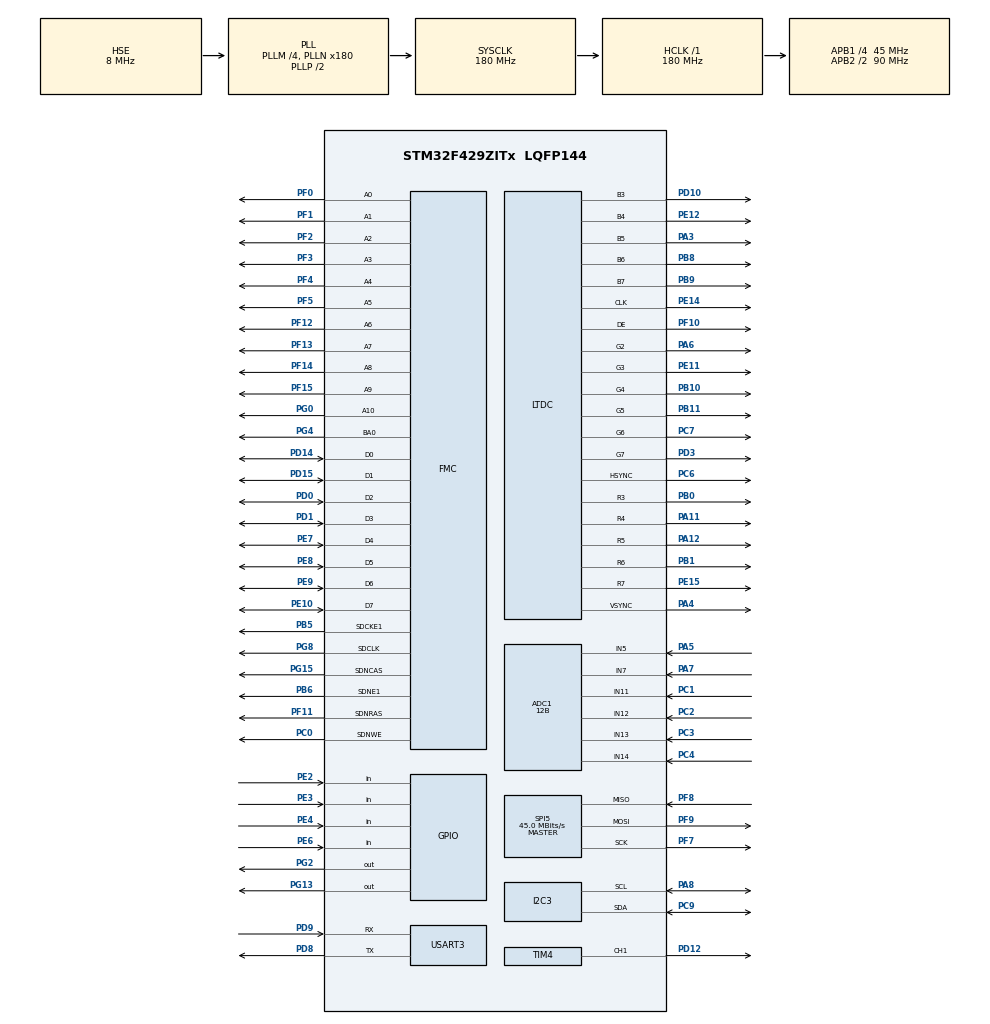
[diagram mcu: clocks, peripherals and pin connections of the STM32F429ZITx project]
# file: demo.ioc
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ADC1.Channel-4\#ChannelRegularConversion=ADC_CHANNEL_5
ADC1.Channel-5\#ChannelRegularConversion=ADC_CHANNEL_7
ADC1.Channel-6\#ChannelRegularConversion=ADC_CHANNEL_11
ADC1.Channel-7\#ChannelRegularConversion=ADC_CHANNEL_12
ADC1.Channel-8\#ChannelRegularConversion=ADC_CHANNEL_13
ADC1.Channel-9\#ChannelRegularConversion=ADC_CHANNEL_14
ADC1.ContinuousConvMode=DISABLE
ADC1.DMAContinuousRequests=DISABLE
ADC1.EOCSelection=ADC_EOC_SEQ_CONV
ADC1.NbrOfConversion=6
ADC1.NbrOfConversionFlag=1
ADC1.Rank-5\#ChannelRegularConversion=2
ADC1.Rank-6\#ChannelRegularConversion=3
ADC1.Rank-7\#ChannelRegularConversion=4
ADC1.Rank-8\#ChannelRegularConversion=5
ADC1.Rank-9\#ChannelRegularConversion=6
ADC1.Resolution=ADC_RESOLUTION_12B
ADC1.SamplingTime-4\#ChannelRegularConversion=ADC_SAMPLETIME_3CYCLES
ADC1.SamplingTime-5\#ChannelRegularConversion=ADC_SAMPLETIME_3CYCLES
ADC1.SamplingTime-6\#ChannelRegularConversion=ADC_SAMPLETIME_3CYCLES
ADC1.SamplingTime-7\#ChannelRegularConversion=ADC_SAMPLETIME_3CYCLES
ADC1.SamplingTime-8\#ChannelRegularConversion=ADC_SAMPLETIME_3CYCLES
ADC1.SamplingTime-9\#ChannelRegularConversion=ADC_SAMPLETIME_3CYCLES
ADC1.master=1
DMA2D.ColorMode=DMA2D_OUTPUT_RGB565
Dma.ADC1.0.Direction=DMA_PERIPH_TO_MEMORY
Dma.ADC1.0.FIFOMode=DMA_FIFOMODE_DISABLE
Dma.ADC1.0.Instance=DMA2_Stream4
Dma.ADC1.0.MemDataAlignment=DMA_MDATAALIGN_HALFWORD
Dma.ADC1.0.MemInc=DMA_MINC_ENABLE
Dma.ADC1.0.Mode=DMA_CIRCULAR
Dma.ADC1.0.PeriphDataAlignment=DMA_PDATAALIGN_HALFWORD
Dma.ADC1.0.PeriphInc=DMA_PINC_DISABLE
Dma.ADC1.0.Priority=DMA_PRIORITY_HIGH
Dma.Request0=ADC1
Dma.Request1=TIM4_CH1
Dma.Request2=USART3_TX
Dma.TIM4_CH1.1.Direction=DMA_MEMORY_TO_PERIPH
Dma.TIM4_CH1.1.FIFOMode=DMA_FIFOMODE_DISABLE
Dma.TIM4_CH1.1.Instance=DMA1_Stream0
Dma.TIM4_CH1.1.MemDataAlignment=DMA_MDATAALIGN_HALFWORD
Dma.TIM4_CH1.1.MemInc=DMA_MINC_ENABLE
Dma.TIM4_CH1.1.Mode=DMA_NORMAL
Dma.TIM4_CH1.1.PeriphDataAlignment=DMA_PDATAALIGN_HALFWORD
Dma.TIM4_CH1.1.PeriphInc=DMA_PINC_DISABLE
Dma.TIM4_CH1.1.Priority=DMA_PRIORITY_LOW
Dma.USART3_TX.2.Direction=DMA_MEMORY_TO_PERIPH
Dma.USART3_TX.2.FIFOMode=DMA_FIFOMODE_DISABLE
Dma.USART3_TX.2.Instance=DMA1_Stream3
Dma.USART3_TX.2.MemDataAlignment=DMA_MDATAALIGN_BYTE
Dma.USART3_TX.2.MemInc=DMA_MINC_ENABLE
Dma.USART3_TX.2.Mode=DMA_NORMAL
Dma.USART3_TX.2.PeriphDataAlignment=DMA_PDATAALIGN_BYTE
Dma.USART3_TX.2.PeriphInc=DMA_PINC_DISABLE
Dma.USART3_TX.2.Priority=DMA_PRIORITY_MEDIUM
Mcu.Family=STM32F4
Mcu.Name=STM32F429ZITx
Mcu.Package=LQFP144
NVIC.DMA1_Stream0_IRQn=true\:0\:0\:false\:false\:true\:false\:true\:true
NVIC.DMA1_Stream3_IRQn=true\:0\:0\:false\:false\:true\:false\:true\:true
NVIC.DMA2_Stream4_IRQn=true\:0\:0\:false\:false\:true\:false\:true\:true
NVIC.PriorityGroup=NVIC_PRIORITYGROUP_4
NVIC.USART3_IRQn=true\:0\:0\:false\:false\:true\:true\:true\:true
PA11.Mode=RGB565
PA11.Signal=LTDC_R4
PA12.Mode=RGB565
PA12.Signal=LTDC_R5
PA13.Mode=Serial_Wire
PA13.Signal=SYS_JTMS-SWDIO
PA14.Mode=Serial_Wire
PA14.Signal=SYS_JTCK-SWCLK
PA3.Mode=RGB565
PA3.Signal=LTDC_B5
PA4.Mode=RGB565
PA4.Signal=LTDC_VSYNC
PA5.Signal=ADCx_IN5
PA6.Mode=RGB565
PA6.Signal=LTDC_G2
PA7.Signal=ADCx_IN7
PA8.Mode=I2C
PA8.Signal=I2C3_SCL
PB0.Mode=RGB565
PB0.Signal=LTDC_R3
PB1.Mode=RGB565
PB1.Signal=LTDC_R6
PB10.Mode=RGB565
PB10.Signal=LTDC_G4
PB11.Mode=RGB565
PB11.Signal=LTDC_G5
PB5.Mode=SdramChipSelect2_1
PB5.Signal=FMC_SDCKE1
PB6.Mode=SdramChipSelect2_1
PB6.Signal=FMC_SDNE1
PB8.Mode=RGB565
PB8.Signal=LTDC_B6
PB9.Mode=RGB565
PB9.Signal=LTDC_B7
PC0.Signal=FMC_SDNWE
PC1.Signal=ADCx_IN11
PC2.Signal=ADCx_IN12
PC3.Signal=ADCx_IN13
PC4.Signal=ADCx_IN14
PC6.Mode=RGB565
PC6.Signal=LTDC_HSYNC
PC7.Mode=RGB565
PC7.Signal=LTDC_G6
PC9.Mode=I2C
PC9.Signal=I2C3_SDA
PD0.Signal=FMC_D2_DA2
PD1.Signal=FMC_D3_DA3
PD10.Mode=RGB565
PD10.Signal=LTDC_B3
PD12.Signal=S_TIM4_CH1
PD14.Signal=FMC_D0_DA0
PD15.Signal=FMC_D1_DA1
PD3.Mode=RGB565
PD3.Signal=LTDC_G7
PD8.Mode=Asynchronous
PD8.Signal=USART3_TX
PD9.Mode=Asynchronous
PD9.Signal=USART3_RX
PE10.Signal=FMC_D7_DA7
PE11.Mode=RGB565
PE11.Signal=LTDC_G3
PE12.Mode=RGB565
PE12.Signal=LTDC_B4
PE14.Mode=RGB565
PE14.Signal=LTDC_CLK
PE15.Mode=RGB565
PE15.Signal=LTDC_R7
PE2.Signal=GPIO_Input
PE3.Signal=GPIO_Input
PE4.Signal=GPIO_Input
PE6.Signal=GPIO_Input
PE7.Signal=FMC_D4_DA4
PE8.Signal=FMC_D5_DA5
PE9.Signal=FMC_D6_DA6
PF0.Signal=FMC_A0
PF1.Signal=FMC_A1
PF10.Mode=RGB565
PF10.Signal=LTDC_DE
PF11.Signal=FMC_SDNRAS
PF12.Signal=FMC_A6
PF13.Signal=FMC_A7
PF14.Signal=FMC_A8
PF15.Signal=FMC_A9
PF2.Signal=FMC_A2
PF3.Signal=FMC_A3
PF4.Signal=FMC_A4
PF5.Signal=FMC_A5
PF7.Mode=Full_Duplex_Master
PF7.Signal=SPI5_SCK
PF8.Mode=Full_Duplex_Master
PF8.Signal=SPI5_MISO
PF9.Mode=Full_Duplex_Master
PF9.Signal=SPI5_MOSI
PG0.Signal=FMC_A10
PG13.GPIO_Speed=GPIO_SPEED_FREQ_HIGH
PG13.Signal=GPIO_Output
PG15.Signal=FMC_SDNCAS
PG2.Signal=GPIO_Output
PG4.Signal=FMC_A14_BA0
PG8.Signal=FMC_SDCLK
PH0/OSC_IN.Mode=HSE-External-Clock-Source
PH0/OSC_IN.Signal=RCC_OSC_IN
PH1/OSC_OUT.Mode=HSE-External-Clock-Source
PH1/OSC_OUT.Signal=RCC_OSC_OUT
ProjectManager.HeapSize=0x200
ProjectManager.StackSize=0x400
ProjectManager.TargetToolchain=STM32CubeIDE
RCC.48MHZClocksFreq_Value=90000000
RCC.AHBFreq_Value=180000000
RCC.APB1CLKDivider=RCC_HCLK_DIV4
RCC.APB1Freq_Value=45000000
RCC.APB1TimFreq_Value=90000000
RCC.APB2CLKDivider=RCC_HCLK_DIV2
RCC.APB2Freq_Value=90000000
RCC.APB2TimFreq_Value=180000000
RCC.CortexFreq_Value=180000000
RCC.HCLKFreq_Value=180000000
RCC.HSE_VALUE=8000000
RCC.HSI_VALUE=16000000
RCC.LSE_VALUE=32768
RCC.PLLM=4
RCC.PLLN=180
RCC.PLLSAIN=50
RCC.PLLSAIR=4
RCC.PLLSourceVirtual=RCC_PLLSOURCE_HSE
RCC.SYSCLKFreq_VALUE=180000000
RCC.SYSCLKSource=RCC_SYSCLKSOURCE_PLLCLK
RCC.VCOOutputFreq_Value=360000000
SH.ADCx_IN11.0=ADC1_IN11,IN11
SH.ADCx_IN12.0=ADC1_IN12,IN12
SH.ADCx_IN13.0=ADC1_IN13,IN13
SH.ADCx_IN14.0=ADC1_IN14,IN14
SH.ADCx_IN5.0=ADC1_IN5,IN5
SH.ADCx_IN7.0=ADC1_IN7,IN7
SH.FMC_A0.0=FMC_A0,11b-sda1
SH.FMC_A1.0=FMC_A1,11b-sda1
SH.FMC_A10.0=FMC_A10,11b-sda1
SH.FMC_A14_BA0.0=FMC_BA0,TwoSdramBanks1
SH.FMC_A2.0=FMC_A2,11b-sda1
SH.FMC_A3.0=FMC_A3,11b-sda1
SH.FMC_A4.0=FMC_A4,11b-sda1
SH.FMC_A5.0=FMC_A5,11b-sda1
SH.FMC_A6.0=FMC_A6,11b-sda1
SH.FMC_A7.0=FMC_A7,11b-sda1
SH.FMC_A8.0=FMC_A8,11b-sda1
SH.FMC_A9.0=FMC_A9,11b-sda1
SH.FMC_D0_DA0.0=FMC_D0,sd-8b-d1
SH.FMC_D1_DA1.0=FMC_D1,sd-8b-d1
SH.FMC_D2_DA2.0=FMC_D2,sd-8b-d1
SH.FMC_D3_DA3.0=FMC_D3,sd-8b-d1
SH.FMC_D4_DA4.0=FMC_D4,sd-8b-d1
SH.FMC_D5_DA5.0=FMC_D5,sd-8b-d1
SH.FMC_D6_DA6.0=FMC_D6,sd-8b-d1
SH.FMC_D7_DA7.0=FMC_D7,sd-8b-d1
SH.FMC_SDCLK.0=FMC_SDCLK,11b-sda1
SH.FMC_SDNCAS.0=FMC_SDNCAS,11b-sda1
SH.FMC_SDNRAS.0=FMC_SDNRAS,11b-sda1
SH.FMC_SDNWE.0=FMC_SDNWE,11b-sda1
SH.S_TIM4_CH1.0=TIM4_CH1,PWM Generation1 CH1
SPI5.CalculateBaudRate=45.0 MBits/s
SPI5.Direction=SPI_DIRECTION_2LINES
SPI5.Mode=SPI_MODE_MASTER
SPI5.VirtualType=VM_MASTER
TIM4.Channel-PWM\ Generation1\ CH1=TIM_CHANNEL_1
TIM4.Period=112-1
USART3.VirtualMode=VM_ASYNC
VP_DMA2D_VS_DMA2D.Mode=DMA2D_Activate
VP_TIM4_VS_ClockSourceINT.Mode=Internal
board=custom

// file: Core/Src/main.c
/* USER CODE BEGIN Header */
/**
 ******************************************************************************
 * @file           : main.c
 * @brief          : Main program body
 ******************************************************************************
 * @attention
 *
 * Copyright (c) 2023 STMicroelectronics.
 * All rights reserved.
 *
 * This software is licensed under terms that can be found in the LICENSE file
 * in the root directory of this software component.
 * If no LICENSE file comes with this software, it is provided AS-IS.
 *
 ******************************************************************************
 */
/* USER CODE END Header */
#include "main.h"
#include "adc.h"
#include "dma.h"
#include "dma2d.h"
#include "i2c.h"
#include "ltdc.h"
#include "spi.h"
#include "tim.h"
#include "usart.h"
#include "gpio.h"
#include "fmc.h"

/* USER CODE BEGIN Includes */
#include <stdlib.h>
#include "MDL_sensors.h"
#include "MDL_led.h"
#include "MDL_lcd.h"
#include "FERpong.h"

/* USER CODE END Includes */

void SystemClock_Config(void);

int main(void)
{

  /* MCU Configuration--------------------------------------------------------*/

  /* Reset of all peripherals, Initializes the Flash interface and the Systick. */
  HAL_Init();

  /* Configure the system clock */
  SystemClock_Config();

  /* Initialize all configured peripherals */
  MX_GPIO_Init();
  MX_DMA_Init();
  MX_ADC1_Init();
  MX_TIM4_Init();
  MX_DMA2D_Init();
  MX_FMC_Init();
  MX_I2C3_Init();
  MX_SPI5_Init();
  MX_LTDC_Init();
  MX_USART3_UART_Init();
  /* USER CODE BEGIN 2 */
  MDL_sensors_init();
  MDL_leds_init();
  MDL_buttons_init();
  MDL_dispenser_init();

//  MDL_LCD_Init(); //funkcija za mjenjanje ledica (MDL_leds_next_round) ne mijenja boju ledice nakon inicijalizacije LCD-a
  MDL_leds_next_round();
//  MDL_leds_next_round();
//  MDL_leds_next_round();
//  MDL_leds_next_round();
//  MDL_leds_next_round();
//  MDL_leds_next_round();
//  MDL_leds_next_round();
//  MDL_leds_next_round();
//  MDL_leds_next_round();

  /* USER CODE END 2 */

  /* Infinite loop */
  /* USER CODE BEGIN WHILE */

//  char a = 'a';
//  HAL_UART_Transmit(&huart3, &a, 1, 10);
// HAL_Delay(100);
//  MDL_leds_next_round();

	while (1) {

//	    set_LED(LED_1, 0, 0, 255);
//	    set_LED(LED_2, 0, 0, 255);
//	    set_LED(LED_3, 0, 0, 255);
//	    set_LED(LED_4, 0, 0, 255);
//	    set_LED(LED_5, 0, 0, 255);
//	    set_LED(LED_6, 0, 0, 255);
//		send();
//		HAL_Delay(300);
	    set_LED(LED_1, 0, 0, 0);
	    set_LED(LED_2, 0, 0, 0);
	    set_LED(LED_3, 0, 0, 0);
	    set_LED(LED_4, 0, 0, 0);
	    set_LED(LED_5, 0, 0, 0);
	    set_LED(LED_6, 0, 0, 0);
		send();
		HAL_Delay(300);
    /* USER CODE END WHILE */

    /* USER CODE BEGIN 3 */

//		  MDL_leds_next_round();
//		  HAL_Delay(1000);
		  //MDL_leds_win();
		  //HAL_Delay(1000);
//		MDL_sensors_handler();
//		MDL_Buttons_Handler();

	}
  /* USER CODE END 3 */
}

void SystemClock_Config(void)
{
  RCC_OscInitTypeDef RCC_OscInitStruct = {0};
  RCC_ClkInitTypeDef RCC_ClkInitStruct = {0};

  /** Configure the main internal regulator output voltage
  */
  __HAL_RCC_PWR_CLK_ENABLE();
  __HAL_PWR_VOLTAGESCALING_CONFIG(PWR_REGULATOR_VOLTAGE_SCALE1);

  /** Initializes the RCC Oscillators according to the specified parameters
  * in the RCC_OscInitTypeDef structure.
  */
  RCC_OscInitStruct.OscillatorType = RCC_OSCILLATORTYPE_HSE;
  RCC_OscInitStruct.HSEState = RCC_HSE_BYPASS;
  RCC_OscInitStruct.PLL.PLLState = RCC_PLL_ON;
  RCC_OscInitStruct.PLL.PLLSource = RCC_PLLSOURCE_HSE;
  RCC_OscInitStruct.PLL.PLLM = 4;
  RCC_OscInitStruct.PLL.PLLN = 180;
  RCC_OscInitStruct.PLL.PLLP = RCC_PLLP_DIV2;
  RCC_OscInitStruct.PLL.PLLQ = 4;
  if (HAL_RCC_OscConfig(&RCC_OscInitStruct) != HAL_OK)
  {
    Error_Handler();
  }

  /** Activate the Over-Drive mode
  */
  if (HAL_PWREx_EnableOverDrive() != HAL_OK)
  {
    Error_Handler();
  }

  /** Initializes the CPU, AHB and APB buses clocks
  */
  RCC_ClkInitStruct.ClockType = RCC_CLOCKTYPE_HCLK|RCC_CLOCKTYPE_SYSCLK
                              |RCC_CLOCKTYPE_PCLK1|RCC_CLOCKTYPE_PCLK2;
  RCC_ClkInitStruct.SYSCLKSource = RCC_SYSCLKSOURCE_PLLCLK;
  RCC_ClkInitStruct.AHBCLKDivider = RCC_SYSCLK_DIV1;
  RCC_ClkInitStruct.APB1CLKDivider = RCC_HCLK_DIV4;
  RCC_ClkInitStruct.APB2CLKDivider = RCC_HCLK_DIV2;

  if (HAL_RCC_ClockConfig(&RCC_ClkInitStruct, FLASH_LATENCY_5) != HAL_OK)
  {
    Error_Handler();
  }
}

void Error_Handler(void)
{
	__disable_irq();
	while (1) {
	}
}
